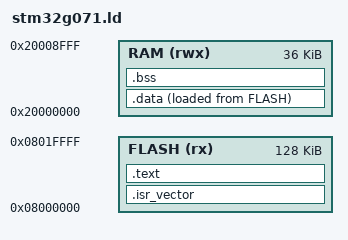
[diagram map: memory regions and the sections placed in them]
MEMORY
{
    FLASH (rx) : ORIGIN = 0x08000000, LENGTH = 128K
    RAM (rwx)  : ORIGIN = 0x20000000, LENGTH = 36K
}

ENTRY(Reset_Handler)

SECTIONS
{
    .isr_vector : {
        KEEP(*(.isr_vector))
    } > FLASH

    .text : {
        *(.text*)
        *(.rodata*)
        _etext = .;
    } > FLASH

    _sidata = LOADADDR(.data);

    .data : {
        _sdata = .;
        *(.data*)
        _edata = .;
    } > RAM AT > FLASH

    .bss : {
        _sbss = .;
        *(.bss*)
        *(COMMON)
        _ebss = .;
    } > RAM

    _estack = ORIGIN(RAM) + LENGTH(RAM);
}
